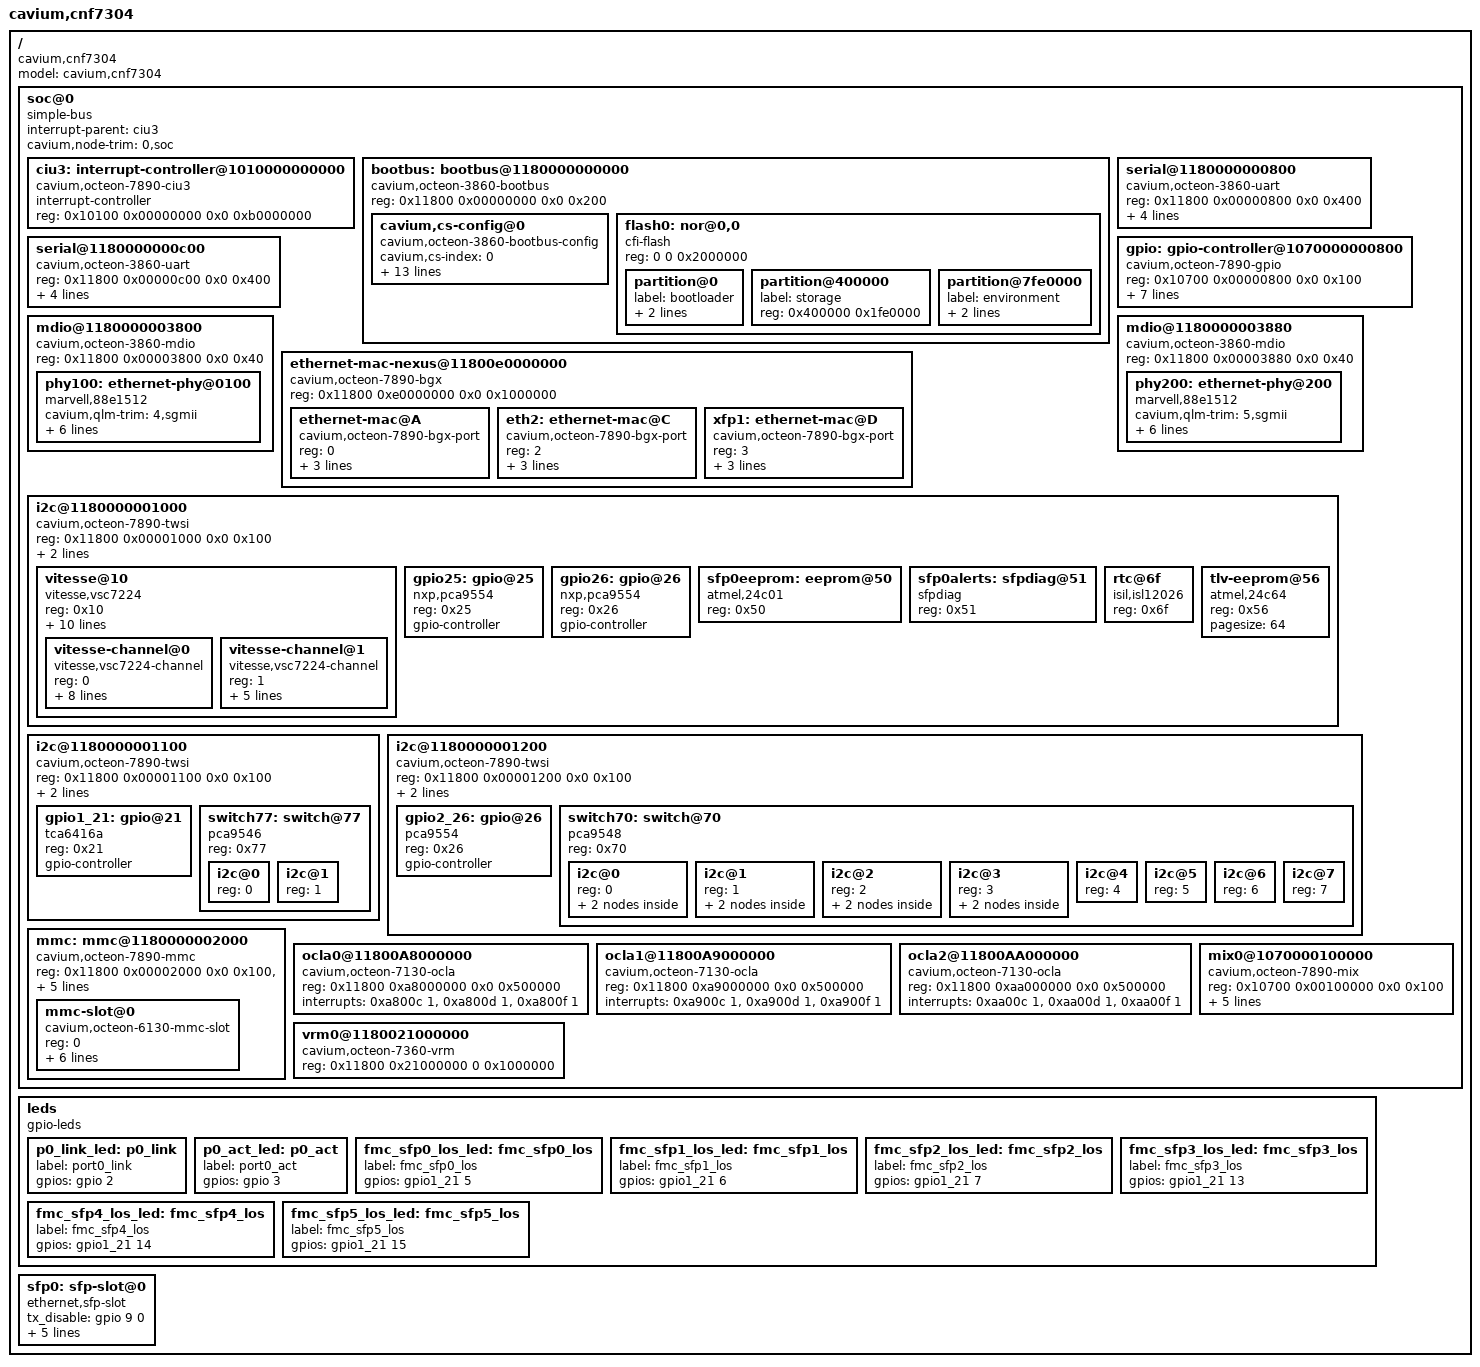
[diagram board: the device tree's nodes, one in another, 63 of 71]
/dts-v1/;
/*
 * Cavium Inc. CRB CNF7300
 */
/ {
	model = "cavium,cnf7304";
	compatible = "cavium,cnf7304";
	#address-cells = <2>;
	#size-cells = <2>;

	soc@0 {
		interrupt-parent = <&ciu3>;
		compatible = "simple-bus";
		#address-cells = <2>;
		#size-cells = <2>;
		ranges; /* Direct mapping */
		cavium,node-trim = "0,soc";

		ciu3: interrupt-controller@1010000000000 {
			compatible = "cavium,octeon-7890-ciu3";
			interrupt-controller;
			/* Interrupts are specified by two parts:
			 * 1) Source number (20 significant bits)
			 * 2) Trigger type: (4 == level, 1 == edge)
			 */
			#address-cells = <0>;
			#interrupt-cells = <2>;
			reg = <0x10100 0x00000000 0x0 0xb0000000>;
		};

		bootbus: bootbus@1180000000000 {
			compatible = "cavium,octeon-3860-bootbus";
			reg = <0x11800 0x00000000 0x0 0x200>;
			/* The chip select number and offset */
			#address-cells = <2>;
			/* The size of the chip select region */
			#size-cells = <1>;
			ranges = <0 0  0x0     0x1dc00000  0x2400000>,
				 <1 0  0x10000 0x10000000  0>,
				 <2 0  0x10000 0x20000000  0>,
				 <3 0  0x10000 0x30000000  0>,
				 <4 0  0x10000 0x40000000  0>,
				 <5 0  0x10000 0x50000000  0>,
				 <6 0  0x10000 0x60000000  0>,
				 <7 0  0x10000 0x70000000  0>;

			cavium,cs-config@0 {
				compatible = "cavium,octeon-3860-bootbus-config";
				cavium,cs-index = <0>;
				cavium,t-adr  = <15>;
				cavium,t-ce   = <55>;
				cavium,t-oe   = <55>;
				cavium,t-we   = <40>;
				cavium,t-rd-hld = <30>;
				cavium,t-wr-hld = <40>;
				cavium,t-pause  = <0>;
				cavium,t-wait   = <65>;
				cavium,t-page   = <35>;
				cavium,t-rd-dly = <0>;

				cavium,page-mode = <1>;
				cavium,pages     = <8>;
				cavium,bus-width = <8>;
			};
			flash0: nor@0,0 {
				compatible = "cfi-flash";
				reg = <0 0 0x2000000>;
				#address-cells = <1>;
				#size-cells = <1>;

				partition@0 {
					label = "bootloader";
					reg = <0 0x400000>;
					read-only;
				};
				partition@400000 {
					label = "storage";
					reg = <0x400000 0x1fe0000>;
				};
				partition@7fe0000 {
					label = "environment";
					reg = <0x1fe00000 0x20000>;
					read-only;
				};
			};
		};

		serial@1180000000800 {
			compatible = "cavium,octeon-3860-uart","ns16550";
			reg = <0x11800 0x00000800 0x0 0x400>;
			clock-frequency = <0>;
			current-speed = <115200>;
			reg-shift = <3>;
			interrupts = <0x08000 4>;
		};

		serial@1180000000c00 {
			compatible = "cavium,octeon-3860-uart","ns16550";
			reg = <0x11800 0x00000c00 0x0 0x400>;
			clock-frequency = <0>;
			current-speed = <115200>;
			reg-shift = <3>;
			interrupts = <0x08040 4>;
		};

		gpio: gpio-controller@1070000000800 {
			#gpio-cells = <2>;
			compatible = "cavium,octeon-7890-gpio";
			reg = <0x10700 0x00000800 0x0 0x100>;
			gpio-controller;
			/* Interrupts are specified by two parts:
			 * 1) GPIO pin number (0..15)
			 * 2) Triggering (1 - edge rising
			 *		  2 - edge falling
			 *		  4 - level active high
			 *		  8 - level active low)
			 */
			interrupt-controller;
			#interrupt-cells = <2>;
			/* The GPIO pins connect to 16 consecutive CUI bits */
			interrupts = <0x03000 4>, <0x03001 4>,
				     <0x03002 4>, <0x03003 4>,
				     <0x03004 4>, <0x03005 4>,
				     <0x03006 4>, <0x03007 4>,
				     <0x03008 4>, <0x03009 4>,
				     <0x0300a 4>, <0x0300b 4>,
				     <0x0300c 4>, <0x0300d 4>,
				     <0x0300e 4>, <0x0300f 4>;
		};

		/* SMI_0 -- The only bus connected on Rev 1 boards */
		mdio@1180000003800 {
			compatible = "cavium,octeon-3860-mdio";
			#address-cells = <1>;
			#size-cells = <0>;
			reg = <0x11800 0x00003800 0x0 0x40>;

			/**
			 * The phy names are broken down as follows:
			 * (m)phyxxyzzs
			 * where:
			 *	xx = 01 for SGMII, 10 for DXAUI, 20 for RXAUI
			 *	     and 40 for XFI/LXAUI
			 *	y = QLM/DLM number
			 *	zz = PHY address (decimal)
			 *	s = sub-phy number in the case of the Cortina
			 *	    PHY
			 * a mphy is a nexus phy that contains one or more
			 * sub-phys, for example the Cortina CS4223.
			 */

			/* DLM 4 */
			phy100: ethernet-phy@0100 {
				cavium,qlm-trim = "4,sgmii";
				reg = <0x0>;
				compatible = "marvell,88e1512", "ethernet-phy-ieee802.3-c22";
				interrupt-parent = <&gpio>;
				interrupts = <5 8>;

				marvell,reg-init = <3 0x10 0 0x8665>,
						   <3 0x11 0 0x00aa>,
						   <3 0x12 0 0x4105>,
						   <3 0x13 0 0x8a08>;
			};
		};

		/* SMI_1 -- The only bus connected on Rev 1 boards */
		mdio@1180000003880 {
			compatible = "cavium,octeon-3860-mdio";
			#address-cells = <1>;
			#size-cells = <0>;
			reg = <0x11800 0x00003880 0x0 0x40>;
			/* DLM 5 */
			phy200: ethernet-phy@200 {
				cavium,qlm-trim = "5,sgmii";
				reg = <0x0>;
				compatible = "marvell,88e1512", "ethernet-phy-ieee802.3-c22";
				interrupt-parent = <&gpio>;
				interrupts = <5 8>; /* Pin 11, active low */

				marvell,reg-init = <3 0x10 0 0x8665>,
						   <3 0x11 0 0x00aa>,
						   <3 0x12 0 0x4105>,
						   <3 0x13 0 0x8a08>;
			};
		};

		/* BGX definitions here must match sim_board.c settings. */
		/* BGX 0*/
		ethernet-mac-nexus@11800e0000000 {
			compatible = "cavium,octeon-7890-bgx";
			reg = <0x11800 0xe0000000 0x0 0x1000000>;
			#address-cells = <1>;
			#size-cells = <0>;

			/* SerDes 0, may differ from PCS Lane/LMAC */
			ethernet-mac@A {
				compatible = "cavium,octeon-7890-bgx-port";
				reg = <0>;
				local-mac-address = [ 00 00 00 00 00 00 ];
				phy-handle = <&phy100>;
				cavium,qlm-trim = "4,sgmii";
			};
			/* SerDes 2 (SGMII) */
			eth2: ethernet-mac@C {
				compatible = "cavium,octeon-7890-bgx-port";
				reg = <2>;
				local-mac-address = [ 00 00 00 00 00 00 ];
				phy-handle = <&phy200>;
				cavium,qlm-trim = "5,sgmii";
			};
			/* SerDes 2, (XFI) may differ from PCS Lane/LMAC */
			xfp1: ethernet-mac@D {
				compatible = "cavium,octeon-7890-bgx-port";
				reg = <3>;
				local-mac-address = [ 00 00 00 00 00 00 ];
				cavium,qlm-trim = "5,xfi";
				sfp-slot = <&sfp0>;
			};
		};

		i2c@1180000001000 {
			#address-cells = <1>;
			#size-cells = <0>;
			compatible = "cavium,octeon-7890-twsi";
			reg = <0x11800 0x00001000 0x0 0x100>;
			/* INT_ST, INT_TS, INT_CORE */
			interrupts = <0x0b000 1>, <0x0b001 1>, <0x0b002 1>;
			clock-frequency = <100000>;

			vitesse@10 {
				compatible = "vitesse,vsc7224";
				reg = <0x10>;
				#address-cells = <1>;
				#size-cells = <0>;
				/* Note that reset is active high with this
				 * device.
				 */
				reset = <&gpio26 1 0>;

				/* LoS pin can be pulled low when there is a
				 * loss of signal.
				 */
				los = <&gpio26 0 0>;
				cavium,qlm-trim = "5,xfi";

				vitesse,reg-init =
					/* Clear all masks */
					/* Page select FSYNC0 (0x30) */
					<0x7f 0x0030>,
					/* Set FSYNC0 for 10.3125Gbps */
					<0x80 0x2841>,	/* See Table 3. */
					<0x81 0x0008>,
					<0x82 0x7a00>,
					<0x83 0x000f>,
					<0x84 0x9c18>,

					/* All channels Rx settings set equally */
					<0x7f 0x0050>,
					/* Shrink EQ_BUFF */
					<0x82 0x0021>,
					/* Set EQVGA_ADAP = 1 (enable EQVGA circuitry),
					 * USE_UNIT_GAIN = 1 (EQVGA is in unity gain),
					 * USE_LPF = 0 (VGA adapt not using LPF),
					 * USE_EQVGA = 1 */
					<0x89 0x7f13>,
					/* Select min DFE Delay (DFE_DELAY) */
					<0x90 0x5585>,
					/* Set DFE 1-3 limit (DXMAX) = 32dec,
					 * AP Max limit = 127 decimal
					 */
					<0x92 0x207f>,
					/* Set AP Min limit = 32 decimal */
					<0x93 0x2000>,
					/* Set DFE Averaging to the slowest (DFE_AVG) */
					<0x94 0x0031>,
					/* Set Inductor Bypass OD_IND_BYP = 0 & fastest Rise/Fall */
					<0x9c 0x0000>,
					/* Setting DFE Boost = none. Must set for
					 * rev C (if DFE in adapt mode)
					 */
					<0xaa 0x0888>,
					/* Setting EQ Min = 8 & Max limit = 72 dec.
					 * Must set for rev C, otherwise EQ is 0
					 * (if EQ is in adaptive mode)
					 */
					<0xa8 0x2408>,
					/* Setting EQVGA = 96, when in EQVGA manual mode */
					<0xa9 0x0060>,
					/* Setting SW_BFOCM, bits 15:14 to 01 */
					<0x87 0x4021>,
					/* Turn off adaptive input equalization
					 * and VGA adaptive algorithm control.
					*/
					<0x89 0x7313>,
					/* Turn on adaptive input equalization
					 * and VGA adaptive algorithm control.
					*/
					<0x89 0x7f13>;

				vitesse-channel@0 {
					compatible = "vitesse,vsc7224-channel";
					reg = <0>;
					direction-tx;
					sfp-mac = <&xfp1>;

					/* TAP settings.  The format of this is as
					 * follows:
					 * - cable length in meters, 0 = active or
					 *   optical module
					 * - maintap value
					 * - pretap value
					 * - posttap value
					 *
					 * For the cable length, the value will apply
					 * for that cable length and greater until the
					 * next largest cable length specified.  These
					 * values must be ordered first by channel mask
					 * then by cable length.  These are typically
					 * set for the transmit channels, not the
					 * receive channels.
					 */
					taps = <0 0x0013 0x000f 0x0000>,
					       <1 0x001f 0x000f 0x0004>,
					       <3 0x0014 0x000b 0x0004>,
					       <5 0x0014 0x0009 0x0006>,
					       <7 0x0014 0x000f 0x0000>,
					       <10 0x0012 0x000b 0x0013>;
				};
				vitesse-channel@1 {
					compatible = "vitesse,vsc7224-channel";
					reg = <1>;
					/* Ignore mod_abs and module */
					direction-rx;

					/* Disable pre-tap */
					pretap-disable;

					/* Disable post-tap */
					posttap-disable;

					/* Taps has the following fields:
					 * - cable length (ignored for rx)
					 * - main tap value
					 * - pre tap value
					 * - post tap value
					 *
					 * NOTE: if taps are disabled then they
					 *       are not programmed.
					 */
					taps = <0 0x0a 0x0b 0x10>;

					sfp-mac = <&xfp1>;
				};
			};

			gpio25: gpio@25 {
				compatible = "nxp,pca9554";
				reg = <0x25>;
				gpio-controller;
				#gpio-cells = <2>;
			};
			gpio26: gpio@26 {
				compatible = "nxp,pca9554";
				reg = <0x26>;
				gpio-controller;
				#gpio-cells = <2>;
			};

			sfp0eeprom: eeprom@50 {
				compatible = "atmel,24c01";
				reg = <0x50>;
			};
			sfp0alerts: sfpdiag@51 {
				compatible = "sfpdiag";
				reg = <0x51>;
			};
			rtc@6f {
				compatible = "isil,isl12026";
				reg = <0x6f>;
			};
			tlv-eeprom@56 {
				compatible = "atmel,24c64", "microchip,24lc256";
				reg = <0x56>;
				pagesize = <64>;
			};
		};

		i2c@1180000001100 {
			#address-cells = <1>;
			#size-cells = <0>;
			compatible = "cavium,octeon-7890-twsi";
			reg = <0x11800 0x00001100 0x0 0x100>;
			/* INT_ST, INT_TS, INT_CORE */
			interrupts = <0x0b100 1>, <0x0b101 1>, <0x0b102 1>;
			clock-frequency = <100000>;

			gpio1_21: gpio@21 {
				compatible = "tca6416a", "tca6416";
				reg = <0x21>;
				gpio-controller;
				#gpio-cells = <2>;
			};

			switch77: switch@77 {
				compatible = "pca9546", "nxp,pca9546";
				reg = <0x77>;
				#address-cells = <1>;
				#size-cells = <0>;

				i2c@0 {
					#address-cells = <1>;
					#size-cells = <0>;
					reg = <0>;
				};
				i2c@1 {
					#address-cells = <1>;
					#size-cells = <0>;
					reg = <1>;
				};
			};
		};

		i2c@1180000001200 {
			#address-cells = <1>;
			#size-cells = <0>;
			compatible = "cavium,octeon-7890-twsi";
			reg = <0x11800 0x00001200 0x0 0x100>;
			/* INT_ST, INT_TS, INT_CORE */
			interrupts = <0x0b200 1>, <0x0b201 1>, <0x0b202 1>;
			clock-frequency = <100000>;

			gpio2_26: gpio@26 {
				compatible = "pca9554";
				reg = <0x26>;
				gpio-controller;
				#gpio-cells = <2>;
			};

			switch70: switch@70 {
				compatible = "pca9548", "nxp,pca9548";
				reg = <0x70>;
				#address-cells = <1>;
				#size-cells = <0>;

				i2c@0 {
					#address-cells = <1>;
					#size-cells = <0>;
					reg = <0>;

					fmc0_sfp0_eeprom: fmc0_sfp0_eeprom@50 {
						compatible = "atmel,24c01";
						reg = <0x50>;
					};
					fmc0_sfp0_diag: fmc0_sfp0_diag@51 {
						compatible = "sfp-diag";
						reg = <0x51>;
					};
				};
				i2c@1 {
					#address-cells = <1>;
					#size-cells = <0>;
					reg = <1>;

					fmc0_sfp1_eeprom: fmc0_sfp1_eeprom@50 {
						compatible = "atmel,24c01";
						reg = <0x50>;
					};
					fmc0_sfp1_diag: fmc0_sfp1_diag@51 {
						compatible = "sfp-diag";
						reg = <0x51>;
					};
				};
				i2c@2 {
					#address-cells = <1>;
					#size-cells = <0>;
					reg = <2>;

					fmc0_sfp2_eeprom: fmc0_sfp2_eeprom@50 {
						compatible = "atmel,24c01";
						reg = <0x50>;
					};
					fmc0_sfp2_diag: fmc0_sfp2_diag@51 {
						compatible = "sfp-diag";
						reg = <0x51>;
					};
				};
				i2c@3 {
					#address-cells = <1>;
					#size-cells = <0>;
					reg = <3>;

					fmc0_sfp3_eeprom: fmc0_sfp3_eeprom@50 {
						compatible = "atmel,24c01";
						reg = <0x50>;
					};
					fmc0_sfp3_diag: fmc0_sfp3_diag@51 {
						compatible = "sfp-diag";
						reg = <0x51>;
					};
				};
				i2c@4 {
					#address-cells = <1>;
					#size-cells = <0>;
					reg = <4>;
				};
				i2c@5 {
					#address-cells = <1>;
					#size-cells = <0>;
					reg = <5>;
				};
				i2c@6 {
					#address-cells = <1>;
					#size-cells = <0>;
					reg = <6>;
				};
				i2c@7 {
					#address-cells = <1>;
					#size-cells = <0>;
					reg = <7>;
				};
			};
		};

		mmc: mmc@1180000002000 {
			compatible = "cavium,octeon-7890-mmc",
				     "cavium,octeon-7360-mmc";
			reg = <0x11800 0x00002000 0x0 0x100>,
			      <0x11800 0x00000180 0x0 0x20>;
			#address-cells = <1>;
			#size-cells = <0>;
			/* EMM_INT_BUF_DONE,
			   EMM_INT_CMD_DONE,
			   EMM_INT_DMA_DONE,
			   EMM_INT_CMD_ERR,
			   EMM_INT_DMA_ERR,
			   EMM_INT_SWITCH_DONE,
			   EMM_INT_SWITCH_ERR,
			   EMM_DMA_DONE,
			   EMM_DMA_FIFO*/
			interrupts = <0x09040 1>,
				     <0x09041 1>,
				     <0x09042 1>,
				     <0x09043 1>,
				     <0x09044 1>,
				     <0x09045 1>,
				     <0x09046 1>,
				     <0x09000 1>,
				     <0x09001 1>;

			/* Power on GPIO 8, active high */
			power-gpios = <&gpio 8 0>;

			/* The board has two MMC slots
			 * If both are occupied, the speed must be reduced,
			 * as extra data-line load increases slew time,
			 * and dat-skew adjustment does not help significantly.
			 */
			mmc-slot@0 {
				compatible = "cavium,octeon-6130-mmc-slot";
				reg = <0>;
				voltage-ranges = <3300 3300>;
				//spi-max-frequency = <52000000>; // just one
				spi-max-frequency = <37000000>; // both slots
				/* bus width can be 1, 4 or 8 */
				bus-width = <8>; /* new std property */
				cavium,bus-max-width = <8>; /* custom property */
				wp-gpios = <&gpio 22 0>; /* active high */
				cd-gpios = <&gpio 23 1>; /* active low */
			};
		};

		ocla0@11800A8000000 {
			compatible = "cavium,octeon-7130-ocla";
			reg = <0x11800 0xa8000000 0x0 0x500000>;
			interrupts = <0xa800c 1>, /* Fsm0 */
				     <0xa800d 1>, /* Fsm1 */
				     <0xa800f 1>; /* Trigfull */
		};

		ocla1@11800A9000000 {
			compatible = "cavium,octeon-7130-ocla";
			reg = <0x11800 0xa9000000 0x0 0x500000>;
			interrupts = <0xa900c 1>, /* Fsm0 */
				     <0xa900d 1>, /* Fsm1 */
				     <0xa900f 1>; /* Trigfull */
		};

		ocla2@11800AA000000 {
			compatible = "cavium,octeon-7130-ocla";
			reg = <0x11800 0xaa000000 0x0 0x500000>;
			interrupts = <0xaa00c 1>, /* Fsm0 */
				     <0xaa00d 1>, /* Fsm1 */
				     <0xaa00f 1>; /* Trigfull */
		};

		mix0@1070000100000 {
			compatible = "cavium,octeon-7890-mix";
			reg = <0x10700 0x00100000 0x0 0x100>;
			interrupts = <0x10000 1>, /* ODBLOVF */
				     <0x10001 1>, /* IDBLOVF */
				     <0x10002 1>, /* ORTHRESH */
				     <0x10003 1>, /* IRTHRESH */
				     <0x10004 1>, /* DATA_DRP */
				     <0x10005 1>, /* IRUN */
				     <0x10006 1>, /* ORUN */
				     <0x10007 1>; /* TS */
			local-mac-address = [ 00 00 00 00 00 00 ];
			cavium,mac-handle = <0xffff>;
		};

		vrm0@1180021000000 {
			compatible = "cavium,octeon-7360-vrm";
			reg = <0x11800 0x21000000 0 0x1000000>;
		};

	};
	leds: leds {
		compatible = "gpio-leds";
		p0_link_led: p0_link {
			label = "port0_link";
			gpios = <&gpio 2 0>;
		};
		p0_act_led: p0_act {
			label = "port0_act";
			gpios = <&gpio 3 0>;
		};
		fmc_sfp0_los_led: fmc_sfp0_los {
			label = "fmc_sfp0_los";
			gpios = <&gpio1_21 5 0>;
		};
		fmc_sfp1_los_led: fmc_sfp1_los {
			label = "fmc_sfp1_los";
			gpios = <&gpio1_21 6 0>;
		};
		fmc_sfp2_los_led: fmc_sfp2_los {
			label = "fmc_sfp2_los";
			gpios = <&gpio1_21 7 0>;
		};
		fmc_sfp3_los_led: fmc_sfp3_los {
			label = "fmc_sfp3_los";
			gpios = <&gpio1_21 13 0>;
		};
		fmc_sfp4_los_led: fmc_sfp4_los {
			label = "fmc_sfp4_los";
			gpios = <&gpio1_21 14 0>;
		};
		fmc_sfp5_los_led: fmc_sfp5_los {
			label = "fmc_sfp5_los";
			gpios = <&gpio1_21 15 0>;
		};
	};


	sfp0: sfp-slot@0 {
		compatible = "ethernet,sfp-slot";
		tx_disable = <&gpio 9 0>;
		mod_abs = <&gpio26 5 0>;
		tx_error = <&gpio26 6 0>;
		rx_los = <&gpio26 7 0>;
		eeprom = <&sfp0eeprom>;
		diag = <&sfp0alerts>;
	};
 };

